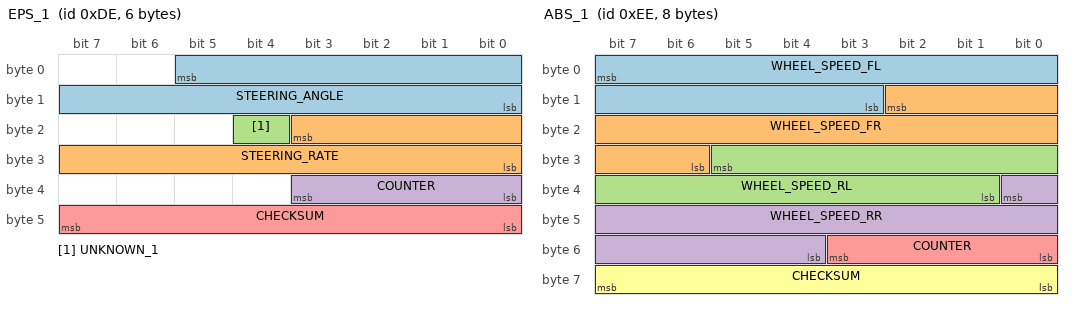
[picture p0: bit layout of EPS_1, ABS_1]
BO_ 222 EPS_1: 6 EPS
 SG_ STEERING_ANGLE : 5|14@0+ (0.1,-700) [0|16383] "deg" XXX
 SG_ STEERING_RATE : 19|12@0+ (0.5,-1000) [0|4095] "deg/s" XXX
 SG_ UNKNOWN_1 : 20|1@0+ (1,0) [0|1] "" XXX
 SG_ COUNTER : 35|4@0+ (1,0) [0|15] "" XXX
 SG_ CHECKSUM : 47|8@0+ (1,0) [0|255] "" XXX

BO_ 238 ABS_1: 8 ABS
 SG_ WHEEL_SPEED_FL : 7|13@0+ (0.017,0) [0|8191] "m/s" XXX
 SG_ WHEEL_SPEED_FR : 10|13@0+ (0.017,0) [0|8191] "m/s" XXX
 SG_ WHEEL_SPEED_RL : 29|13@0+ (0.017,0) [0|8191] "m/s" XXX
 SG_ WHEEL_SPEED_RR : 32|13@0+ (0.017,0) [0|8191] "m/s" XXX
 SG_ COUNTER : 51|4@0+ (1,0) [0|15] "" XXX
 SG_ CHECKSUM : 63|8@0+ (1,0) [0|255] "" XXX

BO_ 241 NEW_MSG_F1: 8 XXX
 SG_ NEW_SIGNAL_1 : 29|6@0+ (1,0) [0|63] "" XXX

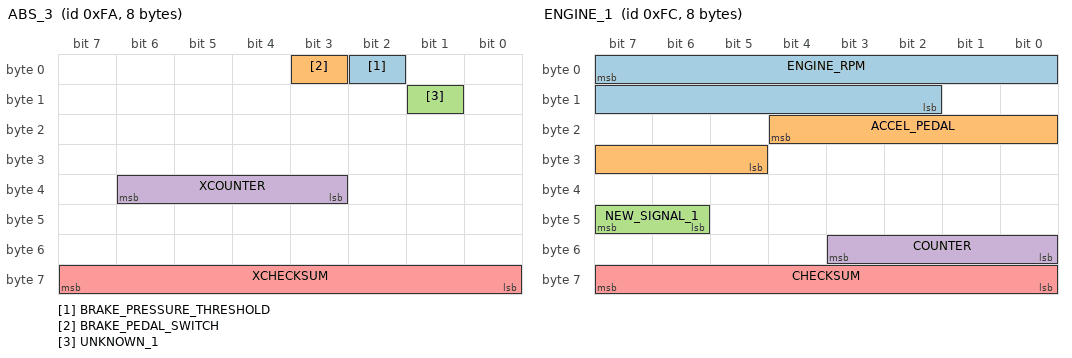
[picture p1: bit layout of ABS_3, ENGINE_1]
BO_ 250 ABS_3: 8 ABS
 SG_ BRAKE_PRESSURE_THRESHOLD : 2|1@0+ (1,0) [0|1] "" XXX
 SG_ BRAKE_PEDAL_SWITCH : 3|1@0+ (1,0) [0|1] "" XXX
 SG_ UNKNOWN_1 : 9|1@0+ (1,0) [0|1] "" XXX
 SG_ XCOUNTER : 38|4@0+ (1,0) [0|15] "" XXX
 SG_ XCHECKSUM : 63|8@0+ (1,0) [0|255] "" XXX

BO_ 252 ENGINE_1: 8 ENGINE
 SG_ ENGINE_RPM : 7|14@0+ (1,0) [0|255] "rev/min" XXX
 SG_ ACCEL_PEDAL : 20|8@0+ (0.4,0) [0|255] "percent" XXX
 SG_ NEW_SIGNAL_1 : 46|2@1+ (1,0) [0|3] "" XXX
 SG_ COUNTER : 51|4@0+ (1,0) [0|15] "" XXX
 SG_ CHECKSUM : 63|8@0+ (1,0) [0|255] "" XXX

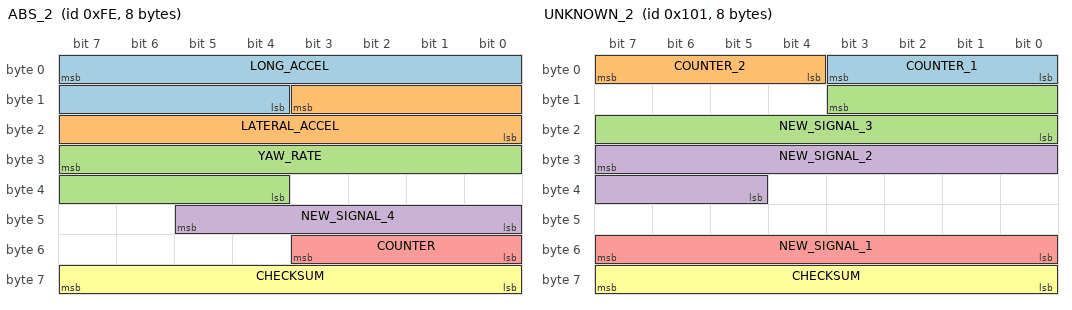
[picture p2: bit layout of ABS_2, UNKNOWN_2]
BO_ 254 ABS_2: 8 ABS
 SG_ LONG_ACCEL : 7|12@0+ (1,-2048) [0|4095] "m/s2" XXX
 SG_ LATERAL_ACCEL : 11|12@0+ (-1,-2048) [0|4095] "m/s2" XXX
 SG_ YAW_RATE : 31|12@0+ (-0.0014,2.86) [0|4095] "rad/s" XXX
 SG_ NEW_SIGNAL_4 : 45|6@0+ (1,0) [0|63] "" XXX
 SG_ COUNTER : 51|4@0+ (1,0) [0|15] "" XXX
 SG_ CHECKSUM : 63|8@0+ (1,0) [0|255] "" XXX

BO_ 257 UNKNOWN_2: 8 XXX
 SG_ COUNTER_1 : 3|4@0+ (1,0) [0|15] "" XXX
 SG_ COUNTER_2 : 7|4@0+ (1,0) [0|15] "" XXX
 SG_ NEW_SIGNAL_3 : 11|12@0+ (1,0) [0|4095] "" XXX
 SG_ NEW_SIGNAL_2 : 31|11@0+ (1,0) [0|2047] "" XXX
 SG_ NEW_SIGNAL_1 : 55|8@0+ (1,0) [0|255] "" XXX
 SG_ CHECKSUM : 63|8@0+ (1,0) [0|255] "" XXX

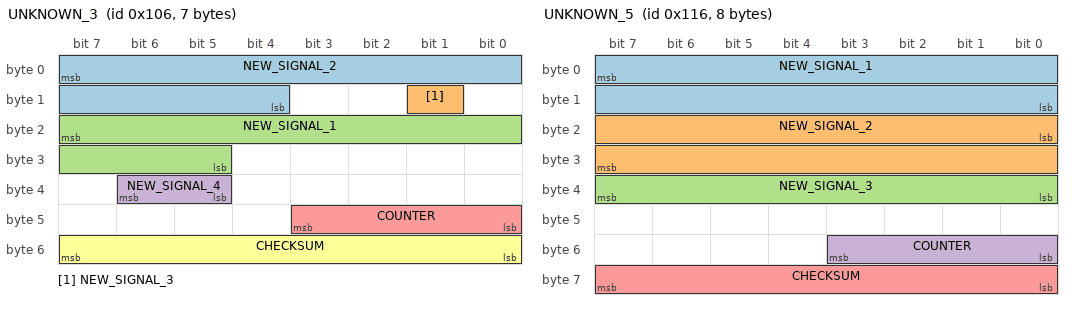
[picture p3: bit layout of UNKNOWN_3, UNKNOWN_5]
BO_ 262 UNKNOWN_3: 7 XXX
 SG_ NEW_SIGNAL_2 : 7|12@0+ (1,0) [0|4095] "" XXX
 SG_ NEW_SIGNAL_3 : 9|1@0+ (1,0) [0|1] "" XXX
 SG_ NEW_SIGNAL_1 : 23|11@0+ (1,0) [0|2047] "" XXX
 SG_ NEW_SIGNAL_4 : 38|2@0+ (1,0) [0|3] "" XXX
 SG_ COUNTER : 43|4@0+ (1,0) [0|15] "" XXX
 SG_ CHECKSUM : 55|8@0+ (1,0) [0|255] "" XXX

BO_ 263 ABS_4: 8 ABS
 SG_ BRAKE_PRESSURE : 7|8@0+ (1,0) [0|255] "" XXX

BO_ 278 UNKNOWN_5: 8 XXX
 SG_ NEW_SIGNAL_1 : 7|16@0+ (1,0) [0|65535] "" XXX
 SG_ NEW_SIGNAL_2 : 16|16@1+ (1,0) [0|65535] "" XXX
 SG_ NEW_SIGNAL_3 : 39|8@0+ (1,0) [0|255] "" XXX
 SG_ COUNTER : 51|4@0+ (1,0) [0|15] "" XXX
 SG_ CHECKSUM : 63|8@0+ (1,0) [0|255] "" XXX

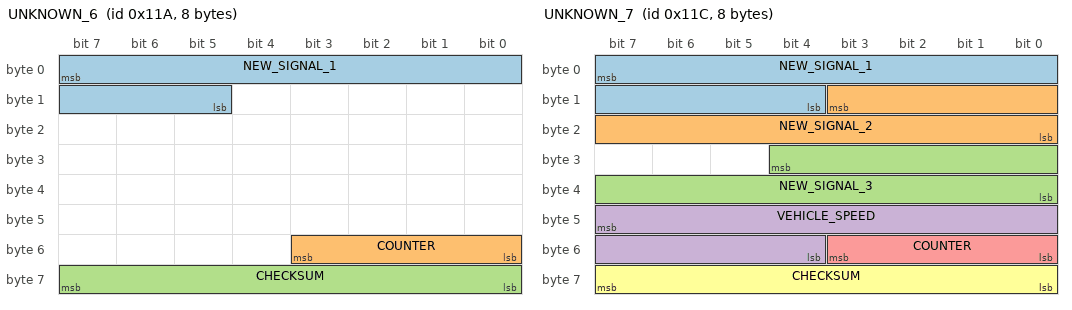
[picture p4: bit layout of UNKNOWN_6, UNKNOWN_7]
BO_ 282 UNKNOWN_6: 8 XXX
 SG_ NEW_SIGNAL_1 : 7|11@0+ (1,0) [0|2047] "" XXX
 SG_ COUNTER : 51|4@0+ (1,0) [0|15] "" XXX
 SG_ CHECKSUM : 63|8@0+ (1,0) [0|255] "" XXX

BO_ 284 UNKNOWN_7: 8 XXX
 SG_ NEW_SIGNAL_1 : 7|12@0+ (1,0) [0|4095] "" XXX
 SG_ NEW_SIGNAL_2 : 11|12@0+ (1,0) [0|4095] "" XXX
 SG_ NEW_SIGNAL_3 : 28|13@0+ (1,0) [0|8191] "" XXX
 SG_ VEHICLE_SPEED : 47|12@0+ (0.017,0) [0|4095] "m/s" XXX
 SG_ COUNTER : 51|4@0+ (1,0) [0|15] "" XXX
 SG_ CHECKSUM : 63|8@0+ (1,0) [0|255] "" XXX

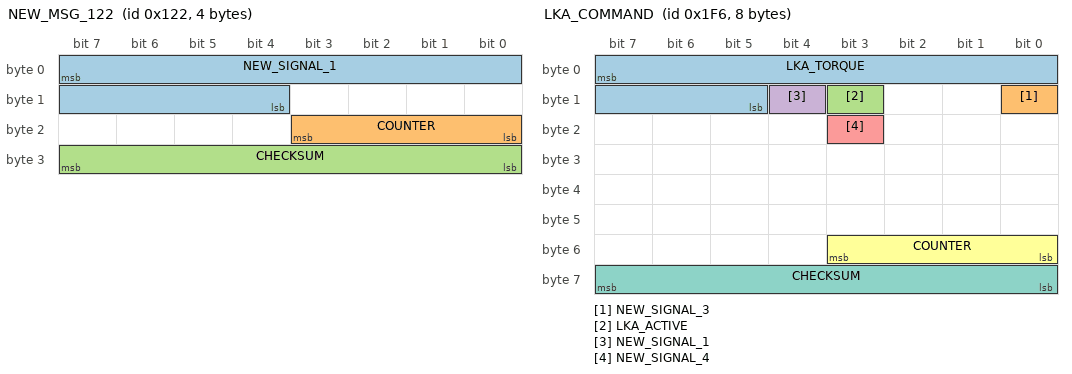
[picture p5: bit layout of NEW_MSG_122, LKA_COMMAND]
BO_ 290 NEW_MSG_122: 4 XXX
 SG_ NEW_SIGNAL_1 : 7|12@0+ (1,0) [0|4095] "" XXX
 SG_ COUNTER : 19|4@0+ (1,0) [0|15] "" XXX
 SG_ CHECKSUM : 31|8@0+ (1,0) [0|255] "" XXX

BO_ 502 LKA_COMMAND: 8 CAMERA
 SG_ LKA_TORQUE : 7|11@0+ (1,-1024) [0|2047] "" XXX
 SG_ NEW_SIGNAL_3 : 8|1@0+ (1,0) [0|1] "" XXX
 SG_ LKA_ACTIVE : 11|1@0+ (1,0) [0|1] "" XXX
 SG_ NEW_SIGNAL_1 : 12|1@0+ (1,0) [0|1] "" XXX
 SG_ NEW_SIGNAL_4 : 19|1@0+ (1,0) [0|1] "" XXX
 SG_ COUNTER : 51|4@0+ (1,0) [0|15] "" XXX
 SG_ CHECKSUM : 63|8@0+ (1,0) [0|255] "" XXX

BO_ 762 NEW_MSG_2FA: 3 XXX
 SG_ NEW_SIGNAL_1 : 7|8@0+ (1,0) [0|255] "" XXX

BO_ 766 CAM_UNKNOWN_1: 4 CAMERA

BO_ 900 NEW_MSG_384: 8 XXX
 SG_ NEW_SIGNAL_1 : 19|3@0+ (1,0) [0|7] "" XXX

BO_ 1040 NEW_MSG_410: 8 XXX
 SG_ NEW_SIGNAL_1 : 23|8@0+ (1,0) [0|255] "" XXX
 SG_ NEW_SIGNAL_2 : 49|1@0+ (1,0) [0|1] "" XXX

BO_ 1194 CAM_UNKNOWN_2: 8 CAMERA

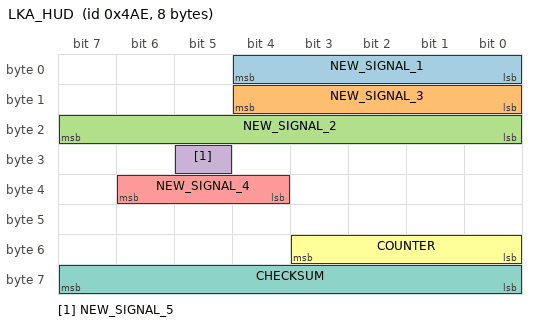
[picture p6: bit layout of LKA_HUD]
BO_ 1198 LKA_HUD: 8 CAMERA
 SG_ NEW_SIGNAL_1 : 4|5@0+ (1,0) [0|31] "" XXX
 SG_ NEW_SIGNAL_3 : 12|5@0+ (1,0) [0|31] "" XXX
 SG_ NEW_SIGNAL_2 : 23|8@0+ (1,0) [0|255] "" XXX
 SG_ NEW_SIGNAL_5 : 29|1@0+ (1,0) [0|1] "" XXX
 SG_ NEW_SIGNAL_4 : 38|3@0+ (1,0) [0|7] "" XXX
 SG_ COUNTER : 51|4@0+ (1,0) [0|15] "" XXX
 SG_ CHECKSUM : 63|8@0+ (1,0) [0|255] "" XXX

BO_ 1351 CAM_UNKNOWN_4: 8 CAMERA

BO_ 1458 CAM_UNKNOWN_5: 4 CAMERA
 SG_ NEW_SIGNAL_1 : 5|1@0+ (1,0) [0|1] "" XXX

BO_ 1854 BCM_1: 4 BCM
 SG_ RIGHT_TURN_STALK : 16|1@0+ (1,0) [0|1] "" XXX
 SG_ LEFT_TURN_STALK : 17|1@0+ (1,0) [0|1] "" XXX

BO_ 506855454 CAM_UNKNOWN_6: 1 CAMERA

CM_ SG_ 254 LONG_ACCEL "scale TBD";
CM_ SG_ 254 LATERAL_ACCEL "scale TBD";
CM_ SG_ 254 YAW_RATE "scale estimated";
CM_ SG_ 284 VEHICLE_SPEED "scale estimated";
CM_ BO_ 1198 "Definite LKA activity, probably contains lane-line recognition and lane departure signals, indicator of LKA vs TJA, perhaps indicator of active assist in map-permitted areas";
